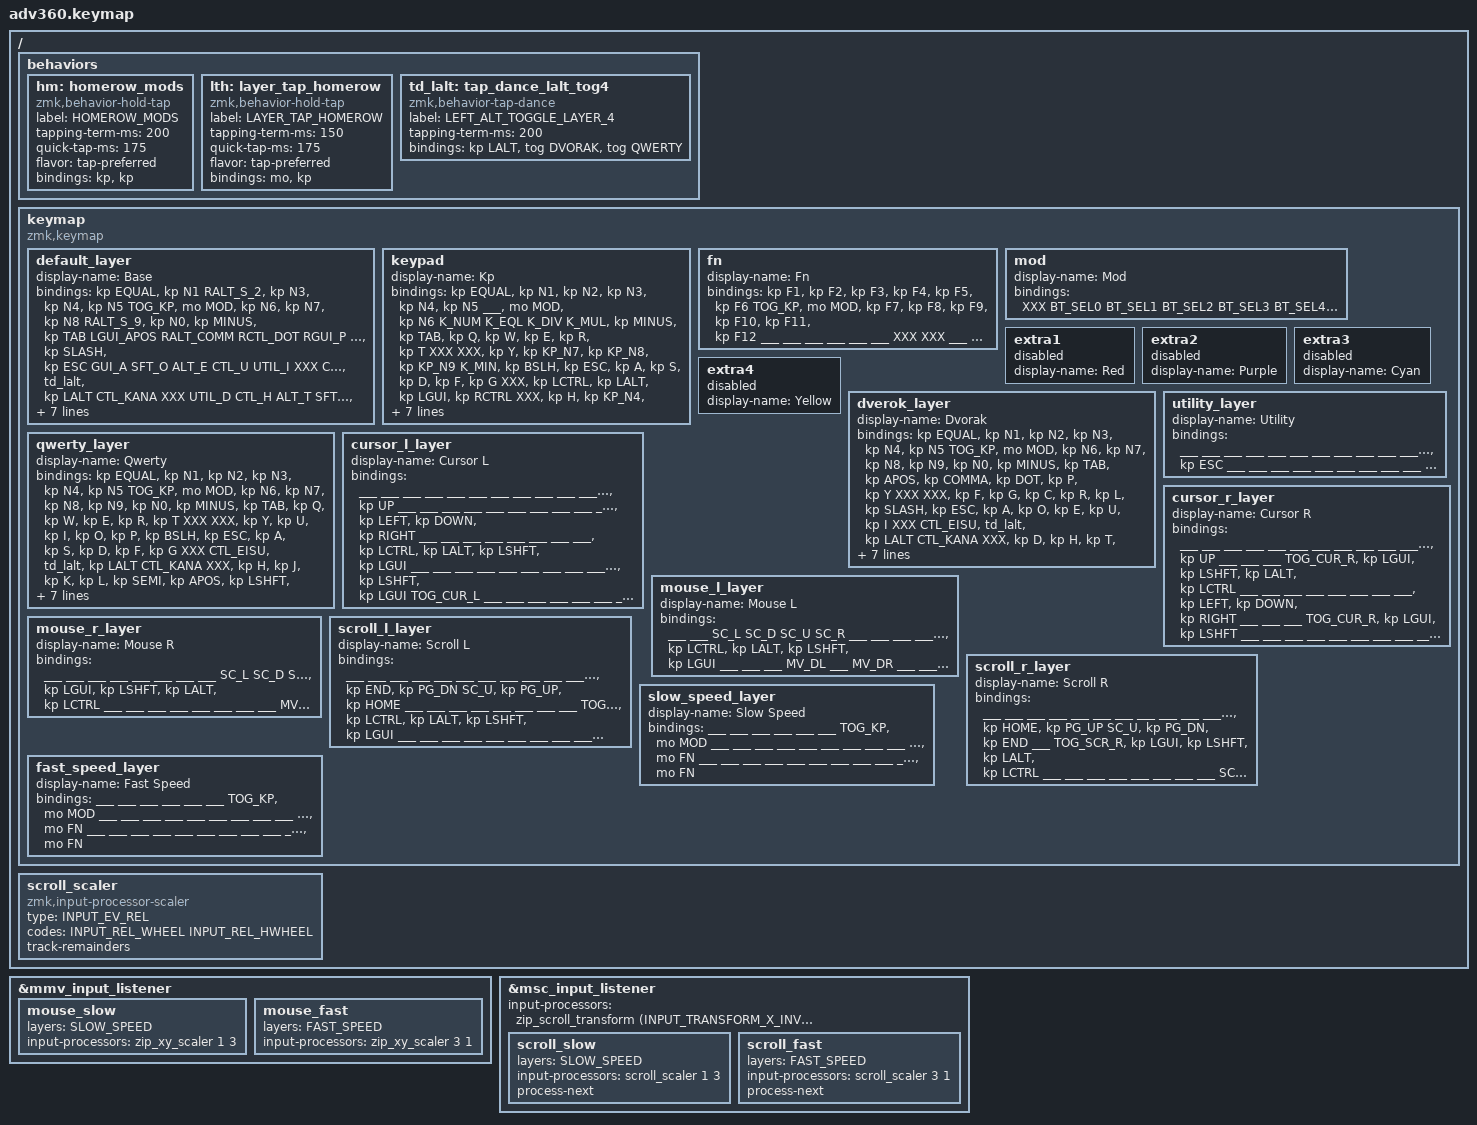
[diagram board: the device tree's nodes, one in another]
#include <behaviors.dtsi>
#include <dt-bindings/zmk/keys.h>
#include <dt-bindings/zmk/bt.h>
#include <dt-bindings/zmk/rgb.h>
#include <dt-bindings/zmk/stp.h>
#include <dt-bindings/zmk/backlight.h>

#define ZMK_POINTING_DEFAULT_MOVE_VAL 840  /* 600 */
#define ZMK_POINTING_DEFAULT_SCRL_VAL 10   /*  10 */
#include <dt-bindings/zmk/pointing.h>
#include <input/processors.dtsi>
#include <dt-bindings/zmk/input_transform.h>

/* Layer indices (keep in sync with the order of layers in keymap)
 *
 * _L / _R of CURSOR / MOUSE / SCROLL: the hand that operates the cursor /
 * mouse / scroll keys. The trigger key and the modifiers are on the other hand.
 */
#define BASE       0
#define KEYPAD     1
#define FN         2
#define MOD        3
#define DVORAK     4
#define QWERTY     5
#define UTIL       6
#define CURSOR_L   7
#define CURSOR_R   8
#define MOUSE_L    9
#define MOUSE_R    10
#define SCROLL_L   11
#define SCROLL_R   12
#define SLOW_SPEED 13
#define FAST_SPEED 14

/* Short aliases so that every layer fits a grid of 10 columns per key */
#define ___       &trans
#define XXX       &none
#define TOG_KP    &tog KEYPAD
#define KANA      &kp LANG1
#define EISU      &kp LANG2
#define CTL_KANA  &mt LCTRL LANG1
#define CTL_EISU  &mt LCTRL LANG2
#define GUI_HOME  &mt LGUI HOME
#define GUI_PGUP  &mt LGUI PG_UP
/* Base layer: home row mods (&hm) and layer-taps (&lth) */
/* RALT + Shift on 2 / 9: the Shift key right below RALT is hard to press together */
#define RALT_S_2  &hm LS(RALT) N2
#define RALT_S_9  &hm LS(RALT) N9
#define LGUI_APOS &hm LGUI APOS
#define RALT_COMM &hm RALT COMMA
#define RCTL_DOT  &hm RCTRL DOT
#define RGUI_P    &hm RGUI P
#define CTL_Y     &hm LCTRL Y
#define CTL_F     &hm LCTRL F
#define RGUI_G    &hm RGUI G
#define RCTL_C    &hm RCTRL C
#define RALT_R    &hm RALT R
#define LGUI_L    &hm LGUI L
#define GUI_A     &hm LGUI A
#define SFT_O     &hm LSHFT O
#define ALT_E     &hm LALT E
#define CTL_U     &hm LCTRL U
#define UTIL_I    &lth UTIL I
#define UTIL_D    &lth UTIL D
#define CTL_H     &hm LCTRL H
#define ALT_T     &hm LALT T
#define SFT_N     &hm LSHFT N
#define GUI_S     &hm LGUI S
#define CUR_SEMI  &lth CURSOR_R SEMI
#define SCR_Q     &lth SCROLL_R Q
#define MOU_J     &lth MOUSE_R J
#define MOU_W     &lth MOUSE_L W
#define SCR_V     &lth SCROLL_L V
#define CUR_Z     &lth CURSOR_L Z
/* Mouse and scroll layers */
#define SLOW      &mo SLOW_SPEED
#define FAST      &mo FAST_SPEED
#define CLK_L     &mkp LCLK
#define CLK_R     &mkp RCLK
#define MV_U      &mmv MOVE_UP
#define MV_D      &mmv MOVE_DOWN
#define MV_L      &mmv MOVE_LEFT
#define MV_R      &mmv MOVE_RIGHT
/* Diagonal mouse moves (X and Y are encoded in separate bits) */
#define MV_UL     &mmv (MOVE_UP | MOVE_LEFT)
#define MV_UR     &mmv (MOVE_UP | MOVE_RIGHT)
#define MV_DL     &mmv (MOVE_DOWN | MOVE_LEFT)
#define MV_DR     &mmv (MOVE_DOWN | MOVE_RIGHT)
#define SC_U      &msc SCRL_UP
#define SC_D      &msc SCRL_DOWN
#define SC_L      &msc SCRL_LEFT
#define SC_R      &msc SCRL_RIGHT
/* Layer locks */
#define TOG_CUR_L &tog CURSOR_L
#define TOG_CUR_R &tog CURSOR_R
#define TOG_MOU_L &tog MOUSE_L
#define TOG_MOU_R &tog MOUSE_R
#define TOG_SCR_L &tog SCROLL_L
#define TOG_SCR_R &tog SCROLL_R
/* Keypad */
#define K_NUM     &kp KP_NUM
#define K_EQL     &kp KP_EQUAL
#define K_DIV     &kp KP_DIVIDE
#define K_MUL     &kp KP_MULTIPLY
#define K_MIN     &kp KP_MINUS
#define K_PLUS    &kp KP_PLUS
#define K_ENT     &kp KP_ENTER
#define K_DOT     &kp KP_DOT
/* Mod layer */
#define BT_SEL0   &bt BT_SEL 0
#define BT_SEL1   &bt BT_SEL 1
#define BT_SEL2   &bt BT_SEL 2
#define BT_SEL3   &bt BT_SEL 3
#define BT_SEL4   &bt BT_SEL 4
#define BT_CLEAR  &bt BT_CLR
#define STUDIO_UL &studio_unlock
#define BOOTLDR   &bootloader
#define stp_BAT   &stp STP_BAT
#define MACRO_VER &macro_ver
#define bl_TOG    &bl BL_TOG
#define bl_INC    &bl BL_INC
#define bl_DEC    &bl BL_DEC
#define rgb_TOG   &rgb_ug RGB_TOG

/ {
    behaviors {
      #include "macros.dtsi"
      #include "version.dtsi"

      hm: homerow_mods {
          compatible = "zmk,behavior-hold-tap";
          label = "HOMEROW_MODS";
          #binding-cells = <2>;
          tapping-term-ms = <200>;
          quick-tap-ms = <175>;
          flavor = "tap-preferred";
          bindings = <&kp>, <&kp>;
      };

      /* Layer-tap on home row keys (same feel as &hm, ported from kanata $lt).
       * tapping-term is shorter than &hm: with 200ms, a quick D(hold)-e(tap)
       * is not decided in time and types "de".
       * Usage: &lth LAYER KEY */
      lth: layer_tap_homerow {
          compatible = "zmk,behavior-hold-tap";
          label = "LAYER_TAP_HOMEROW";
          #binding-cells = <2>;
          tapping-term-ms = <150>;
          quick-tap-ms = <175>;
          flavor = "tap-preferred";
          bindings = <&mo>, <&kp>;
      };

      /* Thumb Ctrl keys use plain &mt (hold-preferred): hold = LCTRL,
       * tap = LANG2 (Eisu) / LANG1 (Kana).
       * Do not combine hold-tap and tap-dance on the same key:
       * - hold-tap inside tap-dance: the hold-tap listener runs before the
       *   tap-dance listener, so a key that interrupts the tap-dance is missed.
       * - tap-dance inside hold-tap: the tap-dance only sees the press when
       *   the key is released, so double taps hardly register. */

      td_lalt: tap_dance_lalt_tog4 {
          compatible = "zmk,behavior-tap-dance";
          label = "LEFT_ALT_TOGGLE_LAYER_4";
          #binding-cells = <0>;
          tapping-term-ms = <200>;
          bindings = <&kp LALT>, <&tog DVORAK>, <&tog QWERTY>;
      };
    };

  keymap {
    compatible = "zmk,keymap";

    /* "layer N -- L, R" = layer LED colors of the left / right modules
     * (see "Layer colors" in README.md) */
    /* layer 0 -- OFF, OFF */
    default_layer {
      display-name = "Base";
      bindings = <
        &kp EQUAL &kp N1    RALT_S_2  &kp N3    &kp N4    &kp N5    TOG_KP                                                                &mo MOD   &kp N6    &kp N7    &kp N8    RALT_S_9  &kp N0    &kp MINUS
        &kp TAB   LGUI_APOS RALT_COMM RCTL_DOT  RGUI_P    CTL_Y     XXX                                                                   XXX       CTL_F     RGUI_G    RCTL_C    RALT_R    LGUI_L    &kp SLASH
        &kp ESC   GUI_A     SFT_O     ALT_E     CTL_U     UTIL_I    XXX                 CTL_EISU  &td_lalt  &kp LALT  CTL_KANA            XXX       UTIL_D    CTL_H     ALT_T     SFT_N     GUI_S     &kp BSLH
        &kp LSHFT CUR_SEMI  SCR_Q     MOU_J     &kp K     &kp X                                   GUI_HOME  GUI_PGUP                                &kp B     &kp M     MOU_W     SCR_V     CUR_Z     &kp RSHFT
        &mo FN    &kp GRAVE &kp CAPS  &kp LEFT  &kp RIGHT                     &kp BSPC  &kp DEL   &kp END   &kp PG_DN &kp ENTER &kp SPACE                     &kp UP    &kp DOWN  &kp LBKT  &kp RBKT  &mo FN
      >;
    };
    /* layer 1 -- WHITE, WHITE */
    keypad {
      display-name = "Kp";
      bindings = <
        &kp EQUAL &kp N1    &kp N2    &kp N3    &kp N4    &kp N5    ___                                                                   &mo MOD   &kp N6    K_NUM     K_EQL     K_DIV     K_MUL     &kp MINUS
        &kp TAB   &kp Q     &kp W     &kp E     &kp R     &kp T     XXX                                                                   XXX       &kp Y     &kp KP_N7 &kp KP_N8 &kp KP_N9 K_MIN     &kp BSLH
        &kp ESC   &kp A     &kp S     &kp D     &kp F     &kp G     XXX                 &kp LCTRL &kp LALT  &kp LGUI  &kp RCTRL           XXX       &kp H     &kp KP_N4 &kp KP_N5 &kp KP_N6 K_PLUS    &kp SQT
        &kp LSHFT &kp Z     &kp X     &kp C     &kp V     &kp B                                   &kp HOME  &kp PG_UP                               &kp N     &kp KP_N1 &kp KP_N2 &kp KP_N3 K_ENT     &kp RSHFT
        &mo FN    &kp GRAVE &kp CAPS  &kp LEFT  &kp RIGHT                     &kp BSPC  &kp DEL   &kp END   &kp PG_DN &kp ENTER &kp KP_N0                     &kp UP    &kp DOWN  K_DOT     &kp RBKT  &mo FN
      >;
    };
    /* layer 2 -- BLUE, BLUE */
    fn {
      display-name = "Fn";
      bindings = <
        &kp F1    &kp F2    &kp F3    &kp F4    &kp F5    &kp F6    TOG_KP                                                                &mo MOD   &kp F7    &kp F8    &kp F9    &kp F10   &kp F11   &kp F12
        ___       ___       ___       ___       ___       ___       XXX                                                                   XXX       ___       ___       ___       ___       ___       ___
        ___       ___       ___       ___       ___       ___       XXX                 ___       ___       ___       ___                 XXX       ___       ___       ___       ___       ___       ___
        ___       ___       ___       ___       ___       ___                                     ___       ___                                     ___       ___       ___       ___       ___       ___
        ___       ___       ___       ___       ___                           ___       ___       ___       ___       ___       ___                           ___       ___       ___       ___       ___
      >;
    };
    /* layer 3 -- GREEN, GREEN */
    mod {
      display-name = "Mod";
      bindings = <
        XXX       BT_SEL0   BT_SEL1   BT_SEL2   BT_SEL3   BT_SEL4   XXX                                                                   ___       XXX       XXX       XXX       XXX       XXX       XXX
        XXX       XXX       XXX       XXX       XXX       XXX       BOOTLDR                                                               BOOTLDR   XXX       XXX       XXX       XXX       XXX       XXX
        STUDIO_UL XXX       XXX       XXX       XXX       XXX       XXX                 XXX       XXX       BT_CLEAR  XXX                 stp_BAT   XXX       XXX       XXX       XXX       XXX       XXX
        XXX       XXX       XXX       XXX       MACRO_VER XXX                                     XXX       XXX                                     XXX       XXX       XXX       XXX       XXX       XXX
        XXX       XXX       XXX       XXX       XXX                           XXX       XXX       XXX       XXX       bl_TOG    rgb_TOG                       bl_INC    bl_DEC    XXX       XXX       XXX
      >;
    };
    extra1 { 
      display-name = "Red";    
      status = "reserved";
    };

    extra2 { 
      display-name = "Purple";    
      status = "reserved";
    };

    extra3 { 
      display-name = "Cyan";    
      status = "reserved";
    };

    extra4 { 
      display-name = "Yellow";    
      status = "reserved";
    };
    /* layer 4 -- RED, RED */
    dverok_layer {
      display-name = "Dvorak";
      bindings = <
        &kp EQUAL &kp N1    &kp N2    &kp N3    &kp N4    &kp N5    TOG_KP                                                                &mo MOD   &kp N6    &kp N7    &kp N8    &kp N9    &kp N0    &kp MINUS
        &kp TAB   &kp APOS  &kp COMMA &kp DOT   &kp P     &kp Y     XXX                                                                   XXX       &kp F     &kp G     &kp C     &kp R     &kp L     &kp SLASH
        &kp ESC   &kp A     &kp O     &kp E     &kp U     &kp I     XXX                 CTL_EISU  &td_lalt  &kp LALT  CTL_KANA            XXX       &kp D     &kp H     &kp T     &kp N     &kp S     &kp BSLH
        &kp LSHFT &kp SEMI  &kp Q     &kp J     &kp K     &kp X                                   GUI_HOME  GUI_PGUP                                &kp B     &kp M     &kp W     &kp V     &kp Z     &kp RSHFT
        &mo FN    &kp GRAVE &kp CAPS  &kp LEFT  &kp RIGHT                     &kp BSPC  &kp DEL   &kp END   &kp PG_DN &kp ENTER &kp SPACE                     &kp UP    &kp DOWN  &kp LBKT  &kp RBKT  &mo FN
      >;
    };
    /* layer 5 -- PURPLE, PURPLE */
    qwerty_layer {
      display-name = "Qwerty";
      bindings = <
        &kp EQUAL &kp N1    &kp N2    &kp N3    &kp N4    &kp N5    TOG_KP                                                                &mo MOD   &kp N6    &kp N7    &kp N8    &kp N9    &kp N0    &kp MINUS
        &kp TAB   &kp Q     &kp W     &kp E     &kp R     &kp T     XXX                                                                   XXX       &kp Y     &kp U     &kp I     &kp O     &kp P     &kp BSLH
        &kp ESC   &kp A     &kp S     &kp D     &kp F     &kp G     XXX                 CTL_EISU  &td_lalt  &kp LALT  CTL_KANA            XXX       &kp H     &kp J     &kp K     &kp L     &kp SEMI  &kp APOS
        &kp LSHFT &kp Z     &kp X     &kp C     &kp V     &kp B                                   GUI_HOME  GUI_PGUP                                &kp N     &kp M     &kp COMMA &kp DOT   &kp SLASH &kp RSHFT
        &mo FN    &kp GRAVE &kp CAPS  &kp LEFT  &kp RIGHT                     &kp BSPC  &kp DEL   &kp END   &kp PG_DN &kp ENTER &kp SPACE                     &kp UP    &kp DOWN  &kp LBKT  &kp RBKT  &mo FN
      >;
    };
    /* layer 6 -- CYAN, CYAN */
    /* hold Dvorak i / d, then e -> Kana, t -> Eisu, . -> Esc */
    utility_layer {
      display-name = "Utility";
      bindings = <
        ___       ___       ___       ___       ___       ___       ___                                                                   ___       ___       ___       ___       ___       ___       ___
        ___       ___       ___       &kp ESC   ___       ___       ___                                                                   ___       ___       ___       ___       ___       ___       ___
        ___       ___       ___       KANA      ___       ___       ___                 ___       ___       ___       ___                 ___       ___       ___       EISU      ___       ___       ___
        ___       TOG_CUR_R TOG_SCR_R TOG_MOU_R ___       ___                                     ___       ___                                     ___       ___       TOG_MOU_L TOG_SCR_L TOG_CUR_L ___
        ___       ___       ___       ___       ___                           ___       ___       ___       ___       ___       ___                           ___       ___       ___       ___       ___
      >;
    };
    /* layer 7 -- YELLOW, YELLOW */
    /* hold Dvorak z, right h t n s = mods, v w = gui / shift,
     * left . / o e u = arrows */
    cursor_l_layer {
      display-name = "Cursor L";
      bindings = <
        ___       ___       ___       ___       ___       ___       ___                                                                   ___       ___       ___       ___       ___       ___       ___
        ___       ___       ___       &kp UP    ___       ___       ___                                                                   ___       ___       ___       ___       ___       ___       ___
        TOG_CUR_L ___       &kp LEFT  &kp DOWN  &kp RIGHT ___       ___                 ___       ___       ___       ___                 ___       ___       &kp LCTRL &kp LALT  &kp LSHFT &kp LGUI  ___
        ___       ___       ___       ___       ___       ___                                     ___       ___                                     ___       ___       &kp LSHFT &kp LGUI  TOG_CUR_L ___
        ___       ___       ___       ___       ___                           ___       ___       ___       ___       ___       ___                           ___       ___       ___       ___       ___
      >;
    };
    /* layer 8 -- WHITE, BLUE */
    /* hold Dvorak ;, left a o e u = mods, q j = gui / shift,
     * right c / h t n = arrows */
    cursor_r_layer {
      display-name = "Cursor R";
      bindings = <
        ___       ___       ___       ___       ___       ___       ___                                                                   ___       ___       ___       ___       ___       ___       ___
        ___       ___       ___       ___       ___       ___       ___                                                                   ___       ___       ___       &kp UP    ___       ___       ___
        TOG_CUR_R &kp LGUI  &kp LSHFT &kp LALT  &kp LCTRL ___       ___                 ___       ___       ___       ___                 ___       ___       &kp LEFT  &kp DOWN  &kp RIGHT ___       ___
        ___       TOG_CUR_R &kp LGUI  &kp LSHFT ___       ___                                     ___       ___                                     ___       ___       ___       ___       ___       ___
        ___       ___       ___       ___       ___                           ___       ___       ___       ___       ___       ___                           ___       ___       ___       ___       ___
      >;
    };
    /* layer 9 -- WHITE, GREEN */
    /* hold Dvorak w, right h t n s = mods, m / v = fast / slow,
     * left . / o e u = move, , p / q k = diagonal, 2 3 4 5 = scroll (vi),
     * thumbs = clicks */
    mouse_l_layer {
      display-name = "Mouse L";
      bindings = <
        ___       ___       SC_L      SC_D      SC_U      SC_R      ___                                                                   ___       ___       ___       ___       ___       ___       ___
        ___       ___       MV_UL     MV_U      MV_UR     ___       ___                                                                   ___       ___       ___       ___       ___       ___       ___
        TOG_MOU_L ___       MV_L      MV_D      MV_R      ___       ___                 ___       ___       ___       ___                 ___       ___       &kp LCTRL &kp LALT  &kp LSHFT &kp LGUI  ___
        ___       ___       MV_DL     ___       MV_DR     ___                                     ___       ___                                     ___       FAST      TOG_MOU_L SLOW      ___       ___
        ___       ___       ___       ___       ___                           CLK_L     CLK_R     ___       ___       CLK_R     CLK_L                         ___       ___       ___       ___       ___
      >;
    };
    /* layer 10 -- WHITE, RED */
    /* hold Dvorak j, left a o e u = mods, k / q = fast / slow,
     * right c / h t n = move, g r / m v = diagonal, 6 7 8 9 = scroll (vi),
     * thumbs = clicks */
    mouse_r_layer {
      display-name = "Mouse R";
      bindings = <
        ___       ___       ___       ___       ___       ___       ___                                                                   ___       SC_L      SC_D      SC_U      SC_R      ___       ___
        ___       ___       ___       ___       ___       ___       ___                                                                   ___       ___       MV_UL     MV_U      MV_UR     ___       ___
        TOG_MOU_R &kp LGUI  &kp LSHFT &kp LALT  &kp LCTRL ___       ___                 ___       ___       ___       ___                 ___       ___       MV_L      MV_D      MV_R      ___       ___
        ___       ___       SLOW      TOG_MOU_R FAST      ___                                     ___       ___                                     ___       MV_DL     ___       MV_DR     ___       ___
        ___       ___       ___       ___       ___                           CLK_L     CLK_R     ___       ___       CLK_R     CLK_L                         ___       ___       ___       ___       ___
      >;
    };
    /* layer 11 -- WHITE, PURPLE */
    /* hold Dvorak v, right h t n s = mods, m / z = fast / slow,
     * left . / o e u = scroll,
     * ' , . p y = end pgdn up pgup home, thumbs = clicks */
    scroll_l_layer {
      display-name = "Scroll L";
      bindings = <
        ___       ___       ___       ___       ___       ___       ___                                                                   ___       ___       ___       ___       ___       ___       ___
        ___       &kp END   &kp PG_DN SC_U      &kp PG_UP &kp HOME  ___                                                                   ___       ___       ___       ___       ___       ___       ___
        TOG_SCR_L ___       SC_L      SC_D      SC_R      ___       ___                 ___       ___       ___       ___                 ___       ___       &kp LCTRL &kp LALT  &kp LSHFT &kp LGUI  ___
        ___       ___       ___       ___       ___       ___                                     ___       ___                                     ___       FAST      ___       TOG_SCR_L SLOW      ___
        ___       ___       ___       ___       ___                           CLK_L     CLK_R     ___       ___       CLK_R     CLK_L                         ___       ___       ___       ___       ___
      >;
    };
    /* layer 12 -- WHITE, CYAN */
    /* hold Dvorak q, left a o e u = mods, k / ; = fast / slow,
     * right c / h t n = scroll,
     * f g c r l = home pgup up pgdn end, thumbs = clicks */
    scroll_r_layer {
      display-name = "Scroll R";
      bindings = <
        ___       ___       ___       ___       ___       ___       ___                                                                   ___       ___       ___       ___       ___       ___       ___
        ___       ___       ___       ___       ___       ___       ___                                                                   ___       &kp HOME  &kp PG_UP SC_U      &kp PG_DN &kp END   ___
        TOG_SCR_R &kp LGUI  &kp LSHFT &kp LALT  &kp LCTRL ___       ___                 ___       ___       ___       ___                 ___       ___       SC_L      SC_D      SC_R      ___       ___
        ___       SLOW      TOG_SCR_R ___       FAST      ___                                     ___       ___                                     ___       ___       ___       ___       ___       ___
        ___       ___       ___       ___       ___                           CLK_L     CLK_R     ___       ___       CLK_R     CLK_L                         ___       ___       ___       ___       ___
      >;
    };
    /* layer 13 -- WHITE, YELLOW */
    slow_speed_layer {
      display-name = "Slow Speed";
      bindings = <
        ___       ___       ___       ___       ___       ___       TOG_KP                                                                &mo MOD   ___       ___       ___       ___       ___       ___
        ___       ___       ___       ___       ___       ___       XXX                                                                   XXX       ___       ___       ___       ___       ___       ___
        ___       ___       ___       ___       ___       ___       XXX                 ___       ___       ___       ___                 XXX       ___       ___       ___       ___       ___       ___
        ___       ___       ___       ___       ___       ___                                     ___       ___                                     ___       ___       ___       ___       ___       ___
        &mo FN    ___       ___       ___       ___                           ___       ___       ___       ___       ___       ___                           ___       ___       ___       ___       &mo FN
      >;
    };
    /* layer 14 -- BLUE, WHITE */
    fast_speed_layer {
      display-name = "Fast Speed";
      bindings = <
        ___       ___       ___       ___       ___       ___       TOG_KP                                                                &mo MOD   ___       ___       ___       ___       ___       ___
        ___       ___       ___       ___       ___       ___       XXX                                                                   XXX       ___       ___       ___       ___       ___       ___
        ___       ___       ___       ___       ___       ___       XXX                 ___       ___       ___       ___                 XXX       ___       ___       ___       ___       ___       ___
        ___       ___       ___       ___       ___       ___                                     ___       ___                                     ___       ___       ___       ___       ___       ___
        &mo FN    ___       ___       ___       ___                           ___       ___       ___       ___       ___       ___                           ___       ___       ___       ___       &mo FN
      >;
    };
  };
};

&mmv_input_listener {
  mouse_slow {
    layers = <SLOW_SPEED>;
    input-processors = <&zip_xy_scaler 1 3>;
  };

  mouse_fast {
    layers = <FAST_SPEED>;
    input-processors = <&zip_xy_scaler 3 1>;
  };
};

/* Scaler for scroll values (this ZMK has no zip_scroll_scaler) */
/ {
  scroll_scaler: scroll_scaler {
    compatible = "zmk,input-processor-scaler";
    #input-processor-cells = <2>;
    type = <INPUT_EV_REL>;
    codes = <INPUT_REL_WHEEL INPUT_REL_HWHEEL>;
    track-remainders;
  };
};

&msc_input_listener {
  input-processors = <&zip_scroll_transform (INPUT_TRANSFORM_X_INVERT | INPUT_TRANSFORM_Y_INVERT)>;

  /* process-next: keep applying the base processors (invert) above */
  scroll_slow {
    layers = <SLOW_SPEED>;
    input-processors = <&scroll_scaler 1 3>;
    process-next;
  };

  scroll_fast {
    layers = <FAST_SPEED>;
    input-processors = <&scroll_scaler 3 1>;
    process-next;
  };
};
